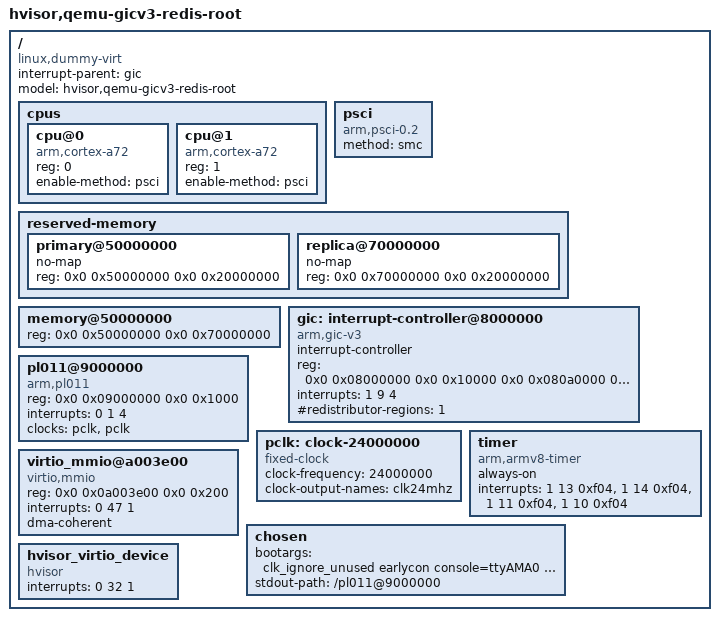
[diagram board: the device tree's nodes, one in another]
/dts-v1/;

/ {
	#address-cells = <2>;
	#size-cells = <2>;
	interrupt-parent = <&gic>;
	model = "hvisor,qemu-gicv3-redis-root";
	compatible = "linux,dummy-virt";

	cpus {
		#address-cells = <1>;
		#size-cells = <0>;

		cpu@0 {
			device_type = "cpu";
			compatible = "arm,cortex-a72";
			reg = <0>;
			enable-method = "psci";
		};

		cpu@1 {
			device_type = "cpu";
			compatible = "arm,cortex-a72";
			reg = <1>;
			enable-method = "psci";
		};
	};

	psci {
		compatible = "arm,psci-0.2";
		method = "smc";
	};

	reserved-memory {
		#address-cells = <2>;
		#size-cells = <2>;
		ranges;

		primary@50000000 {
			no-map;
			reg = <0x0 0x50000000 0x0 0x20000000>;
		};

		replica@70000000 {
			no-map;
			reg = <0x0 0x70000000 0x0 0x20000000>;
		};
	};

	memory@50000000 {
		device_type = "memory";
		reg = <0x0 0x50000000 0x0 0x70000000>;
	};

	gic: interrupt-controller@8000000 {
		compatible = "arm,gic-v3";
		#interrupt-cells = <3>;
		interrupt-controller;
		#address-cells = <2>;
		#size-cells = <2>;
		ranges;
		reg = <0x0 0x08000000 0x0 0x10000
		       0x0 0x080a0000 0x0 0xf60000>;
		interrupts = <1 9 4>;
		#redistributor-regions = <1>;
	};

	pl011@9000000 {
		compatible = "arm,pl011", "arm,primecell";
		reg = <0x0 0x09000000 0x0 0x1000>;
		interrupts = <0 1 4>;
		clocks = <&pclk &pclk>;
		clock-names = "uartclk", "apb_pclk";
	};

	pclk: clock-24000000 {
		compatible = "fixed-clock";
		#clock-cells = <0>;
		clock-frequency = <24000000>;
		clock-output-names = "clk24mhz";
	};

	timer {
		compatible = "arm,armv8-timer", "arm,armv7-timer";
		always-on;
		interrupts = <1 13 0xf04>,
		             <1 14 0xf04>,
		             <1 11 0xf04>,
		             <1 10 0xf04>;
	};

	virtio_mmio@a003e00 {
		compatible = "virtio,mmio";
		reg = <0x0 0x0a003e00 0x0 0x200>;
		interrupts = <0 47 1>;
		dma-coherent;
	};

	chosen {
		bootargs = "clk_ignore_unused earlycon console=ttyAMA0 root=/dev/vda iomem=relaxed rw";
		stdout-path = "/pl011@9000000";
	};

	hvisor_virtio_device {
		compatible = "hvisor";
		interrupts = <0 32 1>;
	};
};
